# core register map
Vendor: litex
Registers are 32-bit, read-write, reset 0x0 unless marked. A register's access mark holds for its fields unless they carry their own. Offsets are from the block's base; [hi:lo] are bit positions; {n}, {i} and the like mark numbered series.

## D11CTIME
Base 0xE0000000
0x00 CONTROL reset 0x61A80
  [31:0] count — Number of ACLK ticks before creating a heart beat
0x04 HEARTBEAT
  [0] beat — Set to `1` at the next `count` interval rollover since `clear` was set.

## SUSRES
Base 0xE0001000
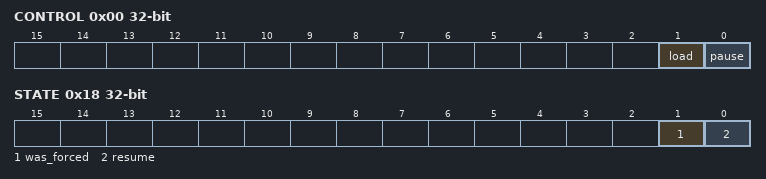
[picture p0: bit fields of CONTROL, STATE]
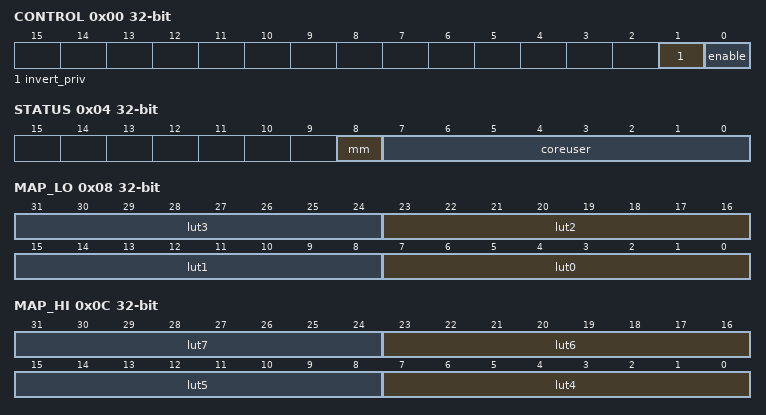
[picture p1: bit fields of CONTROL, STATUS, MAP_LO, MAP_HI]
0x00 CONTROL
  [1] load — If paused, write a `1` to this bit to load a resume value to the timer. If not paused, this bit is ignored.
  [0] pause — Write a `1` to this field to request a pause to counting, 0 for free-run. Count pauses on the next tick quanta.
0x04 RESUME_TIME1 — Bits 32-63 of `SUSRES_RESUME_TIME`. Elapsed time to load. Loaded upon writing `1` to the load bit in the control register. This will immediately affect the msleep extension.
  [31:0] resume_time
0x08 RESUME_TIME0 — Bits 0-31 of `SUSRES_RESUME_TIME`.
  [31:0] resume_time
0x0C TIME1 — Bits 32-63 of `SUSRES_TIME`. Cycle-accurate mirror copy of time in systicks, from the TickTimer
  [31:0] time
0x10 TIME0 — Bits 0-31 of `SUSRES_TIME`.
  [31:0] time
0x14 STATUS
  [0] paused — When set, indicates that the counter has been paused
0x18 STATE
  [1] was_forced — Used by the bootloader to indicate to the kernel if the current resume was from a forced suspend (e.g. a timeout happened and a server may be unclean.
  [0] resume — Used to transfer the resume state information from the loader to Xous. If set, indicates we are on the resume half of a suspend/resume.
0x1C INTERRUPT
  [0] interrupt — Writing this causes an interrupt to fire. Used by Xous to initiate suspend/resume from an interrupt context.
0x20 EV_STATUS — This register contains the current raw level of the soft_int event trigger. Writes to this register have no effect.
  [0] soft_int — Level of the ``soft_int`` event
0x24 EV_PENDING — When a soft_int event occurs, the corresponding bit will be set in this register. To clear the Event, set the corresponding bit in this register.
  [0] soft_int — `1` if a `soft_int` event occurred. This Event is triggered on a **falling** edge.
0x28 EV_ENABLE — This register enables the corresponding soft_int events. Write a ``0`` to this register to disable individual events.
  [0] soft_int — Write a ``1`` to enable the ``soft_int`` Event

## COREUSER
Base 0xE0002000
0x00 CONTROL
  [1] invert_priv — When set to `1` inverts the sense of the privilege bit
  [0] enable — When set to `1`, mappings are enabled. When `0`, the `CoreUser` value is fixed to 0b0001_0000, and the `vex_mm` bit is set to '`1`.
0x04 STATUS
  [8] mm — Computed value of the `mm` signal passed on to the SoC.
  [7:0] coreuser — Computed value of the `CoreUser` signal as passed on to the SoC. For debugging.
0x08 MAP_LO
  [8n+7:8n] lut{n} (n=0..3) — Mapping of `CoreUser` ASID to coreuser dense conding bit 0
0x0C MAP_HI
  [8n-25:8n-32] lut{n} (n=4..7) — Mapping of `CoreUser` ASID to coreuser dense coding bit 1
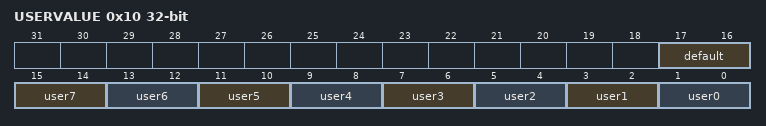
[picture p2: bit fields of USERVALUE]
0x10 USERVALUE
  [17:16] default — Default value of `CoreUser`, for when none of the others match
  [2n+1:2n] user{n} (n=0..7) — Value of `CoreUser` for lut{n} match
0x14 PROTECT — Writing `1` to this bit prevents any further updates to CoreUser configuration status. Can only be reversed with a system reset.
  [0] protect

## CSRTEST
Base 0xE0003000
0x00 WTEST — Write test data here
0x04 RTEST — Read test data here

## IRQARRAY0
Base 0xE0004000
0x00 EV_SOFT — Software interrupt trigger register. ) Bits set to `1` will trigger an interrupt. Interrupts trigger on write, but the value will persist in the register, allowing software to determine if a software interrupt was triggered by reading back the register. Software is responsible for clearing the register to 0. Repeated `1` writes without clearing will still trigger an interrupt.
  [15:0] trigger
0x04 EV_EDGE_TRIGGERED — If a bit is set to 1, then the hardware trigger is edge-triggered
  [15:0] use_edge
0x08 EV_POLARITY — If a bit is set to 1, then the polarity is rising edge triggered; 0 is falling edge triggered. Bit is ignored if `edge_triggered` is 0.
  [15:0] rising
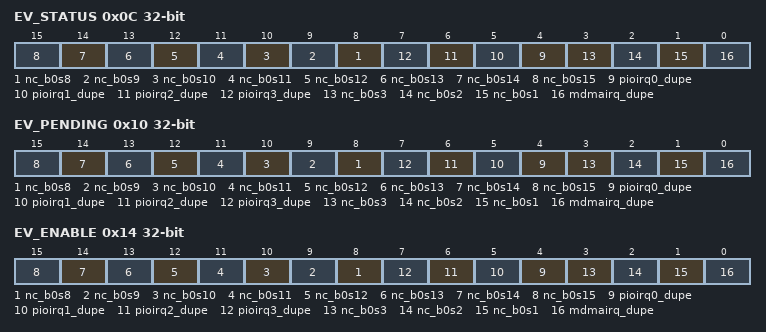
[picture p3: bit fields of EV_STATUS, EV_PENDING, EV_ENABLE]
0x0C EV_STATUS — `1` when a "nc_b0s15" event occurs. This event uses an `EventSourceFlex` form of triggering
  [n] nc_b0s{n} (n=8..15) — Level of the ``nc_b0s{n}`` event
  [n+4] pioirq{n}_dupe (n=0..3) — Level of the ``pioirq{n}_dupe`` event
  [3] nc_b0s3 — Level of the ``nc_b0s3`` event
  [2] nc_b0s2 — Level of the ``nc_b0s2`` event
  [1] nc_b0s1 — Level of the ``nc_b0s1`` event
  [0] mdmairq_dupe — Level of the ``mdmairq_dupe`` event
0x10 EV_PENDING — `1` when a "nc_b0s15" event occurs. This event uses an `EventSourceFlex` form of triggering
  [n] nc_b0s{n} (n=8..15) — `1` when a "nc_b0s{n}" event occurs. This event uses an `EventSourceFlex` form of triggering
  [n+4] pioirq{n}_dupe (n=0..3) — `1` when a "pioirq{n}_dupe" event occurs. This event uses an `EventSourceFlex` form of triggering
  [3] nc_b0s3 — `1` when a "nc_b0s3" event occurs. This event uses an `EventSourceFlex` form of triggering
  [2] nc_b0s2 — `1` when a "nc_b0s2" event occurs. This event uses an `EventSourceFlex` form of triggering
  [1] nc_b0s1 — `1` when a "nc_b0s1" event occurs. This event uses an `EventSourceFlex` form of triggering
  [0] mdmairq_dupe — `1` when a "mdmairq_dupe" event occurs. This event uses an `EventSourceFlex` form of triggering
0x14 EV_ENABLE — `1` when a "nc_b0s15" event occurs. This event uses an `EventSourceFlex` form of triggering
  [n] nc_b0s{n} (n=8..15) — Write a ``1`` to enable the ``nc_b0s{n}`` Event
  [n+4] pioirq{n}_dupe (n=0..3) — Write a ``1`` to enable the ``pioirq{n}_dupe`` Event
  [3] nc_b0s3 — Write a ``1`` to enable the ``nc_b0s3`` Event
  [2] nc_b0s2 — Write a ``1`` to enable the ``nc_b0s2`` Event
  [1] nc_b0s1 — Write a ``1`` to enable the ``nc_b0s1`` Event
  [0] mdmairq_dupe — Write a ``1`` to enable the ``mdmairq_dupe`` Event
